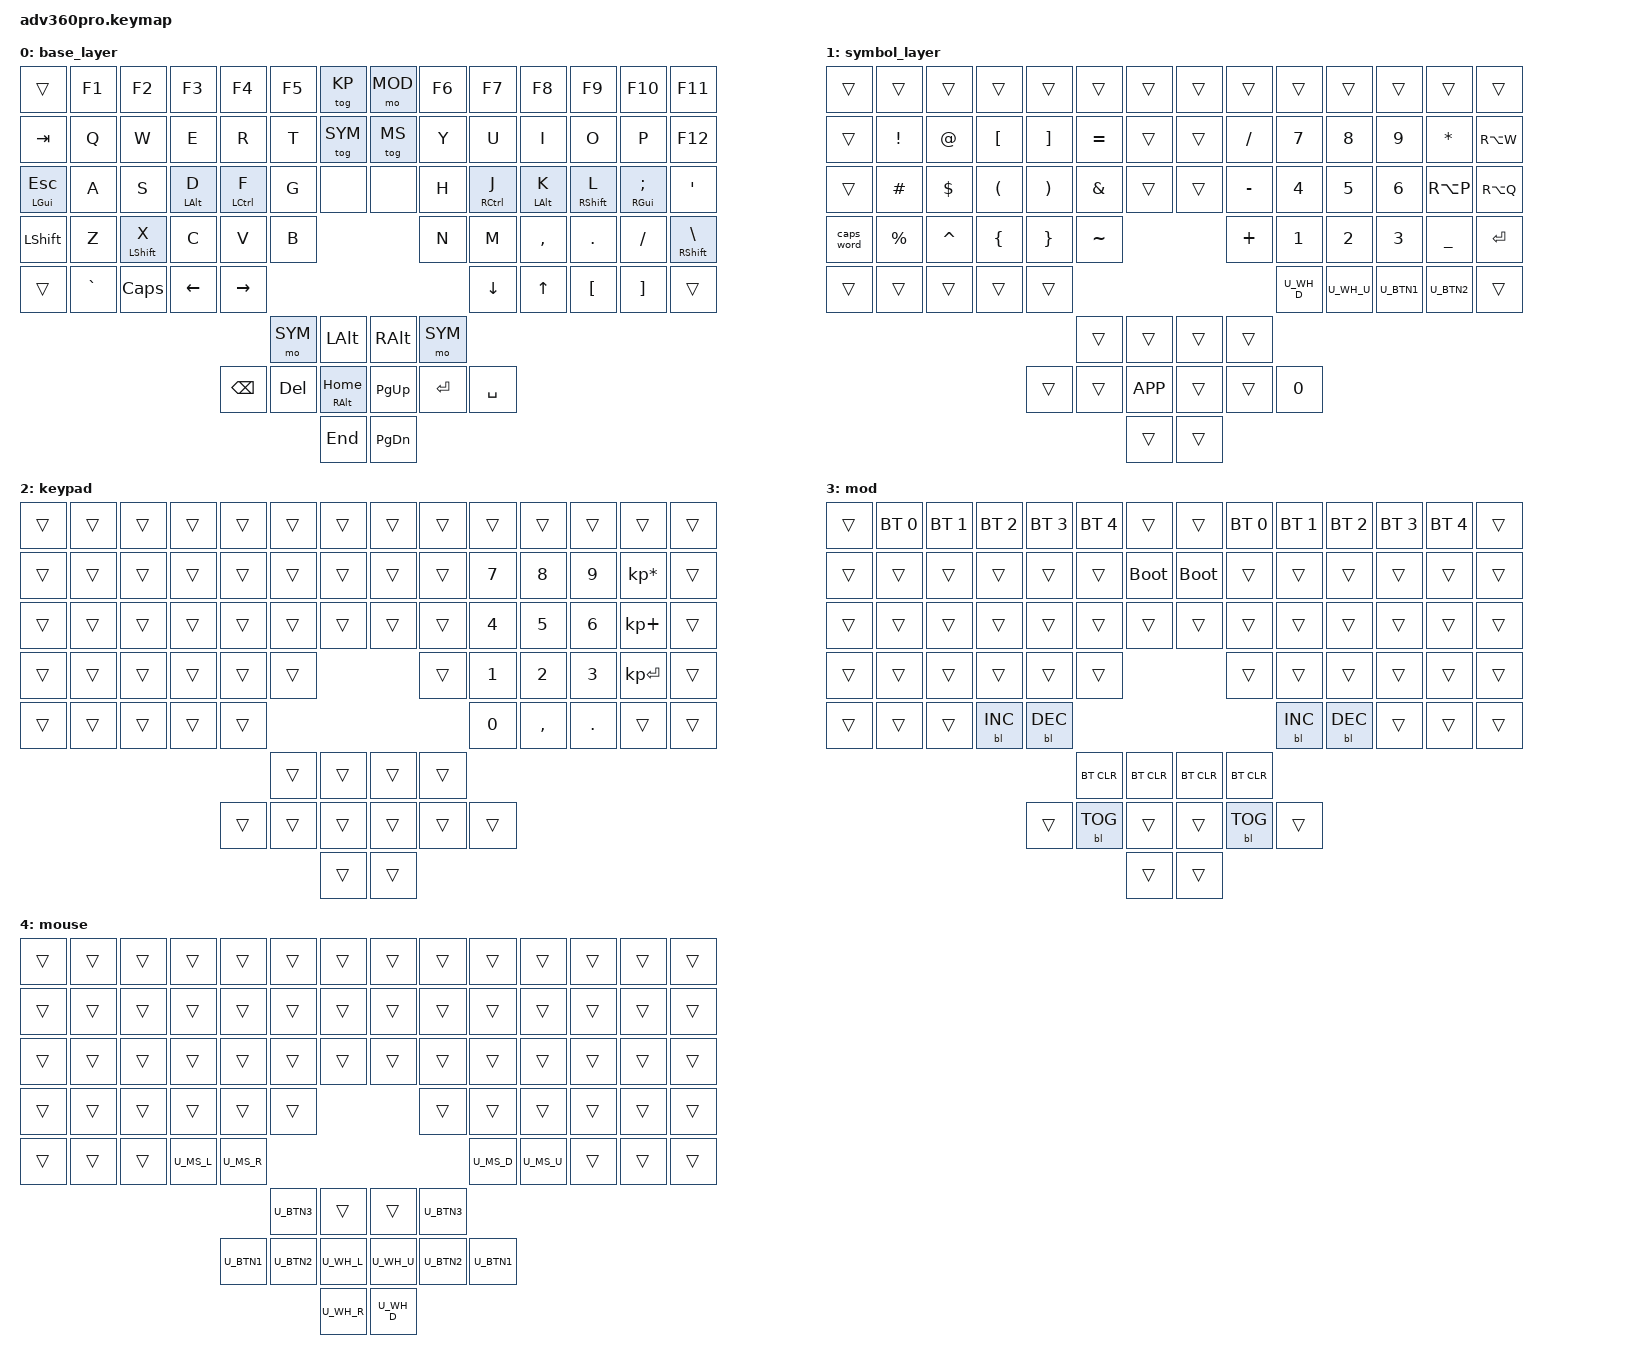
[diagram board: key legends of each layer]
#include <behaviors.dtsi>
#include <dt-bindings/zmk/keys.h>
#include <dt-bindings/zmk/bt.h>
#include <dt-bindings/zmk/outputs.h>
#include <dt-bindings/zmk/rgb.h>
#include <dt-bindings/zmk/backlight.h>

/* definitions for mouse layer */
#include "mouse.dtsi"

#define ___ &trans

#define BASE 0
#define SYM 1
#define KP 2
#define MOD 3
#define MS 4

#define LEFT_KEYS 0 1 2 3 4 5       14 15 16 17 18 19                28 29 30 31 32 33                   43 44 45 46 47                57 58
#define RIGHT_KEYS 8 9 10 11 12 13                    22 23 24 25 26                   36 37 38 39 40 41                48 49 50 51 52       59 60 61 62
#define THUMB_KEYS 64 65 66 67 68 69 70 71 72 73 74 75

// ╭────────────────────────────┬────────────────────────────╮
// │  0   1   2   3   4   5   6 │  7   8   9  10  11  12  13 │
// │ 14  15  16  17  18  19  20 │ 21  22  23  24  25  26  27 │
// │ 28  29  30  31  32  33  34 │ 35  36  37  38  39  40  41 │
// │ 42  43  44  45  46  47 ╭───┴───╮ 48  49  50  51  52  53 │
// │ 54  55  56  57  58╭────╯       ╰────╮59  60  61  62  63 │
// ╰───────────────────┼────────┬────────┼───────────────────╯
//                 ╭───╯ 64  65 │ 66  67 ╰───╮
//                 │ 68  69  70 │ 71  72  73 │
//                 ╰───────╮ 74 │ 75 ╭───────╯
//                         ╰────┴────╯


#define COMBO(NAME, BINDINGS, KEYPOS) \
  combo_##NAME { \
    timeout-ms = <50>; \
    bindings = <BINDINGS>; \
    key-positions = <KEYPOS>; \
    layers = <0>; \
  };

/ {
    /* remove unused keys from layout and move thumb cluster to bottom */
    chosen {
        zmk,matrix_transform = &urobs_transform;
    };

    combos {
        compatible = "zmk,combos";

        COMBO(cut, &kp LS(DEL), 43 44)
        COMBO(copy, &kp LC(INS), 44 45)
        COMBO(paste, &kp LS(INS), 45 46)

        COMBO(colon, &kp COLON, 44 40)
        COMBO(double_quotes, &kp DOUBLE_QUOTES, 44 41)

        COMBO(qmark, &kp QMARK, 44 52)
        COMBO(pipe, &kp PIPE, 44 53)
    };

    behaviors {
        lhm: left_homerow_mods {
            compatible = "zmk,behavior-hold-tap";
            label = "HOMEROW_MODS_LEFT";
            #binding-cells = <2>;
            flavor = "tap-preferred"; // IGNORE_MOD_TAP_INTERRUPT

            tapping-term-ms = <200>;
            quick-tap-ms = <175>;                // repeat on tap-into-hold
            global-quick-tap-ms = <150>;         // requires PR #1387

            hold-trigger-key-positions = <RIGHT_KEYS THUMB_KEYS>;
            hold-trigger-on-release;
            bindings = <&kp>, <&kp>;
        };

        rhm: right_homerow_mods {
            compatible = "zmk,behavior-hold-tap";
            label = "HOMEROW_MODS_RIGHT";
            #binding-cells = <2>;
            flavor = "tap-preferred"; // IGNORE_MOD_TAP_INTERRUPT

            tapping-term-ms = <200>;
            quick-tap-ms = <175>;                // repeat on tap-into-hold
            global-quick-tap-ms = <150>;         // requires PR #1387

            hold-trigger-key-positions = <LEFT_KEYS THUMB_KEYS>;
            hold-trigger-on-release;
            bindings = <&kp>, <&kp>;
        };
    };

    keymap {
        compatible = "zmk,keymap";


        base_layer {
            bindings = <
                &trans       &kp F1    &kp F2       &kp F3       &kp F4        &kp F5    &tog KP            &mo MOD   &kp F6    &kp F7       &kp F8      &kp F9       &kp F10        &kp F11
                &kp TAB      &kp Q     &kp W        &kp E        &kp R         &kp T     &tog SYM           &tog MS   &kp Y     &kp U        &kp I       &kp O        &kp P          &kp F12
                &mt LGUI ESC &kp A     &kp S        &lhm LALT D  &lhm LCTRL F  &kp G     &none              &none     &kp H     &rhm RCTRL J &rhm LALT K &rhm RSHFT L &rhm RGUI SEMI &kp SQT
                &kp LSHFT    &kp Z     &lhm LSHFT X &kp C        &kp V         &kp B                                  &kp N     &kp M        &kp COMMA   &kp DOT      &kp FSLH       &rhm RSHFT BSLH
                &trans       &kp GRAVE &kp CAPS     &kp LEFT     &kp RIGHT                                                      &kp DOWN     &kp UP      &kp LBKT     &kp RBKT       &trans
                                                                               &mo SYM   &kp LALT           &kp RALT  &mo SYM
                                                                 &kp BSPC      &kp DEL   &mt RALT HOME      &kp PG_UP &kp ENTER &kp SPACE
                                                                                         &kp END            &kp PG_DN
            >;
        };

        symbol_layer {
            bindings = <
                ___        ___       ___       ___       ___       ___       ___            ___       ___       ___       ___       ___       ___       ___
                ___        &kp EXCL  &kp AT    &kp LBKT  &kp RBKT  &kp EQUAL ___            ___       &kp FSLH  &kp N7    &kp N8    &kp N9    &kp STAR  &kp RA(W)
                ___        &kp HASH  &kp DLLR  &kp LPAR  &kp RPAR  &kp AMPS  ___            ___       &kp MINUS &kp N4    &kp N5    &kp N6    &kp RA(P) &kp RA(Q)
                &caps_word &kp PRCNT &kp CARET &kp LBRC  &kp RBRC  &kp TILDE                          &kp PLUS  &kp N1    &kp N2    &kp N3    &kp UNDER &kp ENTER
                ___        ___       ___       ___       ___                                                    U_WH_D    U_WH_U    U_BTN1    U_BTN2    ___
                                                                   ___       ___            ___       ___
                                                         ___       ___       &kp K_APP      ___       ___       &kp N0
                                                                             ___            ___
            >;
        };

        keypad {
            bindings = <
                ___       ___       ___       ___       ___       ___       ___            ___       ___       ___        ___          ___           ___             ___
                ___       ___       ___       ___       ___       ___       ___            ___       ___       &kp    N7  &kp    N8    &kp    N9     &kp KP_MULTIPLY ___
                ___       ___       ___       ___       ___       ___       ___            ___       ___       &kp    N4  &kp    N5    &kp    N6     &kp KP_PLUS     ___
                ___       ___       ___       ___       ___       ___                                ___       &kp    N1  &kp    N2    &kp    N3     &kp KP_ENTER    ___
                ___       ___       ___       ___       ___                                                    &kp    N0  &kp    COMMA &kp    DOT    ___             ___
                                                                  ___       ___            ___       ___
                                                        ___       ___       ___            ___       ___       ___
                                                                            ___            ___
            >;
        };

        mod {
            bindings = <
                ___       &bt BT_SEL 0 &bt BT_SEL 1 &bt BT_SEL 2 &bt BT_SEL 3 &bt BT_SEL 4 ___              ___         &bt BT_SEL 0 &bt BT_SEL 1     &bt BT_SEL 2 &bt BT_SEL 3 &bt BT_SEL 4 ___
                ___       ___          ___          ___          ___          ___          &bootloader      &bootloader ___          ___              ___          ___          ___          ___
                ___       ___          ___          ___          ___          ___          ___              ___         ___          ___              ___          ___          ___          ___
                ___       ___          ___          ___          ___          ___                                       ___          ___              ___          ___          ___          ___
                ___       ___          ___          &bl BL_INC   &bl BL_DEC                                                          &bl BL_INC       &bl BL_DEC   ___          ___          ___
                                                                              &bt BT_CLR   &bt BT_CLR       &bt BT_CLR  &bt BT_CLR
                                                                 ___          &bl BL_TOG   ___              ___         &bl BL_TOG   ___
                                                                                           ___              ___
            >;
        };

        mouse {
            bindings = <
                ___       ___       ___       ___       ___       ___       ___            ___       ___       ___       ___       ___       ___       ___
                ___       ___       ___       ___       ___       ___       ___            ___       ___       ___       ___       ___       ___       ___
                ___       ___       ___       ___       ___       ___       ___            ___       ___       ___       ___       ___       ___       ___
                ___       ___       ___       ___       ___       ___                                ___       ___       ___       ___       ___       ___
                ___       ___       ___       U_MS_L    U_MS_R                                                 U_MS_D    U_MS_U    ___       ___       ___
                                                                  U_BTN3    ___            ___       U_BTN3
                                                        U_BTN1    U_BTN2    U_WH_L         U_WH_U    U_BTN2    U_BTN1
                                                                            U_WH_R         U_WH_D
            >;
        };

    };

};

